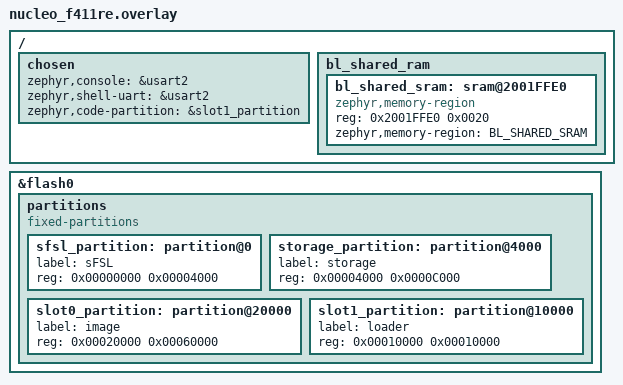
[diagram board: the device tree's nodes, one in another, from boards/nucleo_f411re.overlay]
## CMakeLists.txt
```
# SPDX-License-Identifier: Apache-2.0

cmake_minimum_required(VERSION 3.13.1)

# find_package(Zephyr) in order to load application boilerplate:
# http://docs.zephyrproject.org/application/application.html
find_package(Zephyr REQUIRED HINTS $ENV{ZEPHYR_BASE})

project(sFSL)

zephyr_include_directories(
    ${CMAKE_CURRENT_LIST_DIR}/include
)

zephyr_linker_sources(SECTIONS iterables.ld)

FILE(GLOB app_sources src/main.c src/uart_handle.c src/tshell.c)

target_sources(app PRIVATE ${app_sources})
```

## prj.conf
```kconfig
CONFIG_SBK=y
CONFIG_SBK_MINCRYPT=y
CONFIG_FLASH=y
CONFIG_MAIN_STACK_SIZE=1024
CONFIG_SYSTEM_WORKQUEUE_STACK_SIZE=4096
#CONFIG_PICOLIBC=y

CONFIG_USE_DT_CODE_PARTITION=y
CONFIG_ROM_START_OFFSET=0x200
CONFIG_BOOT_BANNER=n
CONFIG_CONSOLE=y
CONFIG_RING_BUFFER=y
CONFIG_UART_INTERRUPT_DRIVEN=y

CONFIG_LOG=y
CONFIG_SBK_LOG_LEVEL_DBG=y
CONFIG_LOG_MODE_MINIMAL=y
#CONFIG_CBPRINTF_NANO=y
```

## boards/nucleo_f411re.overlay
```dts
/*
 * Copyright (c) 2022 Laczen
 *
 * SPDX-License-Identifier: Apache-2.0
 */

/ {
	chosen {
		zephyr,console = &usart2;
		zephyr,shell-uart = &usart2;
		zephyr,code-partition = &slot1_partition;
	};
};

&flash0 {
	partitions {
		compatible = "fixed-partitions";
		#address-cells = <1>;
		#size-cells = <1>;

		sfsl_partition: partition@0 {
			label = "sFSL";
			reg = <0x00000000 0x00004000>;
		};

		storage_partition: partition@4000 {
			label = "storage";
			reg = <0x00004000 0x0000C000>;
		};

		slot0_partition: partition@20000 {
			label = "image";
			reg = <0x00020000 0x00060000>;
		};

		slot1_partition: partition@10000 {
			label = "loader";
			reg = <0x00010000 0x00010000>;
		};
	};
};

/ {
	bl_shared_ram {
		#address-cells = < 0x1 >;
		#size-cells = < 0x1 >;

		bl_shared_sram: sram@2001FFE0 {
			compatible = "zephyr,memory-region", "mmio-sram";
			reg = < 0x2001FFE0 0x0020 >;
			zephyr,memory-region = "BL_SHARED_SRAM";
		};
	};
};
```

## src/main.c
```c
/*
 * Copyright (c) 2022 Laczen
 *
 * SPDX-License-Identifier: Apache-2.0
 */

#include <stdarg.h>
#include <string.h>
#include <stdio.h>
#include <stdlib.h>
#include <zephyr/kernel.h>
#include <zephyr/drivers/flash.h>
#include <zephyr/device.h>
#include <zephyr/devicetree.h>
#include <zephyr/linker/devicetree_regions.h>

#include "sbk/sbk_image.h"
#include "sbk/sbk_os.h"
#include "sbk/sbk_util.h"
#include "sbk/sbk_product.h"

#include "tshell.h"
#include "uart_handle.h"

#define FLASH_OFFSET CONFIG_FLASH_BASE_ADDRESS

#define SLOT0_NODE		DT_NODELABEL(slot0_partition)
#define SLOT0_MTD               DT_MTD_FROM_FIXED_PARTITION(SLOT0_NODE)
#define SLOT0_DEVICE	        DEVICE_DT_GET(SLOT0_MTD)
#define SLOT0_OFFSET	        DT_REG_ADDR(SLOT0_NODE)
#define SLOT0_SIZE              DT_REG_SIZE(SLOT0_NODE)
#define SLOT1_NODE		DT_NODELABEL(slot1_partition)
#define SLOT1_MTD               DT_MTD_FROM_FIXED_PARTITION(SLOT1_NODE)
#define SLOT1_DEVICE	        DEVICE_DT_GET(SLOT1_MTD)
#define SLOT1_OFFSET	        DT_REG_ADDR(SLOT1_NODE)
#define SLOT1_SIZE              DT_REG_SIZE(SLOT1_NODE)

#define BL_SHARED_SRAM_NODE	DT_NODELABEL(bl_shared_sram)
#define BL_SHARED_SRAM_SECT	LINKER_DT_NODE_REGION_NAME(BL_SHARED_SRAM_NODE)
#define BL_SHARED_SRAM_ADDR	DT_REG_ADDR(BL_SHARED_SRAM_NODE)
#define BL_SHARED_SRAM_SIZE	DT_REG_SIZE(BL_SHARED_SRAM_NODE)

/**
 * @brief shared data format definition
 */

struct sbk_shared_data {
        uint32_t product_hash;
        struct sbk_version product_ver;
        uint8_t bslot;
        uint8_t bcnt;
};

/**
 * @brief Loader slot setup
 * 
 */

struct flash_slot_ctx {
        const struct device *dev;
        uint32_t off;
        uint32_t size;
};

const struct flash_slot_ctx slots[2] = {
        {
                .dev = SLOT0_DEVICE,
                .off = SLOT0_OFFSET,
                .size = SLOT0_SIZE,
        },
        {
                .dev = SLOT1_DEVICE,
                .off = SLOT1_OFFSET,
                .size = SLOT1_SIZE,
        }
};

static int read(const void *ctx, unsigned long off, void *data, size_t len)
{
        const struct flash_slot_ctx *sctx = (const struct flash_slot_ctx *)ctx;

        return flash_read(sctx->dev, sctx->off + off, data, len);
}

static int prog(const void *ctx, unsigned long off, const void *data, size_t len)
{
        const struct flash_slot_ctx *sctx = (const struct flash_slot_ctx *)ctx;
        int rc;

        if (((sctx->off + off) % 0x20000) == 0U) {
                rc = flash_erase(sctx->dev, sctx->off + off, 131072);
                if (rc != 0) {
                        goto end;
                }
        }

        rc = flash_write(sctx->dev, sctx->off + off, data, len);
        //SBK_LOG_DBG("Written %d bytes to %lx [%d]", len, sctx->off + off, rc);
end:
        return rc;
}

static int sync(const void *ctx)
{
        return 0;
}

static unsigned long get_start_address(const void *ctx)
{
        const struct flash_slot_ctx *sctx = (const struct flash_slot_ctx *)ctx;

        return FLASH_OFFSET + sctx->off;
}

static size_t get_size(const void *ctx)
{
        const struct flash_slot_ctx *sctx = (const struct flash_slot_ctx *)ctx;

        return sctx->size;
}

static int slot_init(struct sbk_os_slot *slot, unsigned int slot_no)
{
        if (slot_no >= ARRAY_SIZE(slots)) {
                return -SBK_EC_ENOENT;
        }

        slot->ctx = (void *)&slots[slot_no];
        slot->read = read;
        slot->prog = prog;
        slot->sync = sync;
        slot->get_start_address = get_start_address;
        slot->get_size = get_size;
        return 0;
}

int (*sbk_os_slot_init)(struct sbk_os_slot *slot, unsigned int slot_no) = slot_init;
struct sbk_shared_data shared_data Z_GENERIC_SECTION(BL_SHARED_SRAM);

/**
 * @brief Shell interface
 * 
 */

int cli_command_reboot(const struct tshell *tsh, int argc, char *argv[]) {
        tshell_put(tsh, "Rebooting");
        return 0;
}

#define IMG_BUF_SIZE 512
static size_t ldsize;
static size_t ldoffset;
static bool ldok;
static uint8_t img_buffer[IMG_BUF_SIZE];
static struct sbk_os_slot ldslot;
static struct sbk_image_buffer ldimage_buf = {
        .buf = img_buffer,
        .blen = IMG_BUF_SIZE,
};
static struct sbk_image ldimage = {
        .slot = &ldslot,
        .ib = &ldimage_buf,
};

void cli_load(const struct tshell *tsh, const char *data, size_t len)
{
        if (ldok) {
                if (sbk_image_write(&ldimage, ldoffset, data, len) != 0) {
                        tshell_put(tsh,"Write failed");
                        ldok = false;
                }
        }

        ldsize -= len;
        ldoffset += len;

        if (ldsize == 0U) {
                if (sbk_image_flush(&ldimage) == 0) {
                        tshell_put(tsh, "Write done");
                }

                tshell_set_bypass(tsh, NULL);
                return;
        }

        if ((ldoffset % 256) == 0) {
                tshell_put(tsh, "OK");
        }
}

int cli_command_load(const struct tshell *tsh, int argc, char *argv[]) {
        uint32_t slot;

        if (argc < 2) {
                tshell_put(tsh, "Insufficient arguments");
                return 0;
        }

        slot = strtoul(argv[1], NULL, 0);
        ldsize = strtoul(argv[2], NULL, 0);

        if (sbk_os_slot_open(&ldslot, slot) != 0) {
                tshell_put(tsh, "Bad slot specified");
                return 0;
        }

        if (sbk_os_slot_get_sz(&ldslot) < ldsize) {
                return 0;
        }

        ldoffset = 0U;
        ldok = true;

        char line[81];

        snprintf(line, sizeof(line), "Writing %d bytes to slot %d ...", ldsize, 
                 slot);
        tshell_put(tsh, line);
        tshell_set_bypass(tsh, cli_load);
        tshell_put(tsh, "OK");
        return 0;
}

int cli_command_ilist(const struct tshell *tsh, int argc, char *argv[]) {
        uint32_t slot_no = 0;
        struct sbk_os_slot slot;
        struct sbk_image image = {
                .slot = &slot,
        };
        struct sbk_version version;
	
        while (true) {
                char line[81];
                int rc;

                rc = sbk_os_slot_open(image.slot, slot_no);
                if (rc != 0) {
                        break;
                }
                rc = sbk_image_get_version(&image, &version);
                if (rc != 0) {
                        break;
                }
                snprintf(line, sizeof(line),
                         "Slot %d contains version %d.%d-%d", slot_no,
                         version.major, version.minor, version.revision);
                tshell_put(tsh, line);
                slot_no++;
        }

	return 0;

}

UART_HANDLE_DECLARE(uhndl, DEVICE_DT_GET(DT_CHOSEN(zephyr_console)), 512);
TSHELL_DECLARE(tsh, 64);

TSHELL_REGISTER_CMD(tsh, list, cli_command_ilist, "List images");
TSHELL_REGISTER_CMD(tsh, load, cli_command_load, "Load image to slot: [load slot_no bytes]");
TSHELL_REGISTER_CMD(tsh, reboot, cli_command_reboot, "Reboot device");

void main(void)
{
            
        SBK_LOG_INF("Welcome to %x version %d.%d-%d", shared_data.product_hash,
                shared_data.product_ver.major, 
                shared_data.product_ver.minor,
                shared_data.product_ver.revision);
        SBK_LOG_INF("Running from slot %d", shared_data.bslot);
        SBK_LOG_INF("Boot retries %d", shared_data.bcnt);

        uart_handle_register_rx_cb(&uhndl, tshell_receive, (void *)&tsh);
        tshell_register_send_cb(&tsh, uart_handle_tx, (void *)&uhndl);

        uart_handle_start(&uhndl);
        tshell_start(&tsh);

}
```

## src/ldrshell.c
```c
/*
 * Copyright (c) 2022 Laczen
 *
 * SPDX-License-Identifier: Apache-2.0
 */

#include <zephyr/shell/shell.h>
#include <zephyr/sys/util.h>
#include "sbk/sbk_os.h"
#include "sbk/sbk_product.h"
#include "sbk/sbk_image.h"

#include <stdlib.h>
#include <string.h>

/* Buffer is only needed for bytes that follow command and offset */
#define BUF_ARRAY_CNT (CONFIG_SHELL_ARGC_MAX - 2)

/* This only issues compilation error when it would not be possible
 * to extract at least one byte from command line arguments, yet
 * it does not warrant successful writes if BUF_ARRAY_CNT
 * is smaller than flash write alignment.
 */
BUILD_ASSERT(BUF_ARRAY_CNT >= 1);

#define IMG_BUF_SIZE 512
static struct k_mutex load_lock;
static uint32_t load_total;
static uint32_t load_written;
static uint8_t img_buffer[IMG_BUF_SIZE];
static struct sbk_os_slot load_slot;
static struct sbk_image_buffer load_image_buf = {
        .buf = img_buffer,
        .blen = IMG_BUF_SIZE,
};
static struct sbk_image load_image = {
        .slot = &load_slot,
        .ib = &load_image_buf,
};
static bool load_ok;

static int set_bypass(const struct shell *sh, shell_bypass_cb_t bypass)
{
	static bool in_use;

	if (bypass && in_use) {
		shell_error(sh, "load supports setting bypass on a single instance.");

		return -EBUSY;
	}

	/* Mark that we have set or unset the bypass function */
	in_use = bypass != NULL;

	if (in_use) {
		shell_print(sh, "Loading...");
	}

	shell_set_bypass(sh, bypass);

	return 0;
}


static void bypass_cb(const struct shell *sh, uint8_t *recv, size_t len)
{
	uint32_t left_to_read = load_total - load_written;
	uint32_t to_write = MIN(len, left_to_read);
        int rc;

        k_mutex_lock(&load_lock, K_FOREVER);

        if (load_ok) {
                rc = sbk_image_write(&load_image, load_written, recv, to_write);
                if (rc != 0) {
		        shell_error(sh, "Write failed at position %x [%d]",
			            load_written, rc);
                        load_ok = false;
	        }
        }

        load_written += to_write;

	if (load_written >= load_total) {
                shell_print(sh, "Write complete");
                if (load_ok) {
                        rc = sbk_image_flush(&load_image);
                }

		set_bypass(sh, NULL);
	}

        k_mutex_unlock(&load_lock);
}

static int cmd_load(const struct shell *sh, size_t argc, char *argv[])
{
	uint32_t image_no;

        image_no = strtoul(argv[1], NULL, 0);
	load_total = strtoul(argv[2], NULL, 0);

	/* Prepare image for callback. */
	if (sbk_os_slot_open(&load_slot, image_no) != 0) {
                shell_print(sh, "Error opening slot %d", image_no);
                goto end;                
        }

        load_ok = true;
        load_image.ib->bpos = 0U;
        load_image.ib->bstart = 0U;
        load_written = 0U;
        k_mutex_init(&load_lock);
	shell_print(sh, "Loading %d bytes to slot %d", load_total, image_no);
	set_bypass(sh, bypass_cb);

end:
	return 0;
}

static int cmd_list(const struct shell *sh, size_t argc, char *argv[])
{
	uint32_t slot_no = 0;
        struct sbk_version version;
	
        while (true) {
                int rc;

                rc = sbk_os_slot_open(load_image.slot, slot_no);
                if (rc != 0) {
                        break;
                }
                rc = sbk_image_get_version(&load_image, &version);
                if (rc != 0) {
                        break;
                }
                shell_print(sh, "Slot %d contains version %d.%d-%d", slot_no,
                            version.major, version.minor, version.revision);
                slot_no++;
        }

	return 0;
}

SHELL_STATIC_SUBCMD_SET_CREATE(ldrshell_cmds,
	SHELL_CMD_ARG(load, NULL,
		"<image> <size>",
		cmd_load, 2, 1),
        SHELL_CMD_ARG(list, NULL,
		"list images",
		cmd_list, 0, 1),
	SHELL_SUBCMD_SET_END
);

static int cmd_ldrshell(const struct shell *shell, size_t argc, char **argv)
{
	shell_error(shell, "%s:unknown parameter: %s", argv[0], argv[1]);
	return -EINVAL;
}

SHELL_CMD_ARG_REGISTER(ldrshell, &ldrshell_cmds, "Image loader shell commands",
		       cmd_ldrshell, 2, 0);
```

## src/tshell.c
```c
#include <stdbool.h>
#include <stddef.h>
#include <string.h>
#include <zephyr/kernel.h>
#include "tshell.h"

#define TSHELL_MAX_ARGS (16)
#define TSHELL_PROMPT "tshell> "

void tshell_register_send_cb(struct tshell *tsh,
			     void (*send_cb)(const void *send_cb_ctx, char c),
			     void *send_cb_ctx)
{
	tsh->send_cb = send_cb;
	tsh->send_cb_ctx = send_cb_ctx;
}

static void tshell_send(const struct tshell *tsh, char c)
{
        if (tsh->send_cb == NULL) {
                return;
        }
        return tsh->send_cb(tsh->send_cb_ctx, c);
}

static void tshell_echo(const struct tshell *tsh, char c)
{
        if (c == '\n' || c == '\r') {
                tshell_send(tsh, '\r');
                tshell_send(tsh, '\n');
        }  else {
                tshell_send(tsh, c);
        }
}

static void tshell_echo_str(const struct tshell *tsh, const char *str)
{
        for (const char *c = str; *c != '\0'; ++c) {
                tshell_echo(tsh, *c);
        }
}

static void tshell_send_prompt(const struct tshell *tsh)
{
        tshell_echo_str(tsh, TSHELL_PROMPT);
}

static struct tshell_command *tshell_find_cmd(const struct tshell *tsh,
                                              const char *cmd)
{
        STRUCT_SECTION_FOREACH(tshell_command, h) {
                if ((strcmp(h->sname, tsh->name)==0) && 
                    (strcmp(h->cmd, cmd)== 0)) {
                        return h;
                }
        
        }

        return NULL;
}

static bool tshell_cmdbuf_full(const struct tshell *tsh)
{
  return tsh->tsh_data->cmdbufpos >= tsh->tsh_data->cmdbufsize;
}

static void tshell_cmdbuf_reset(const struct tshell *tsh)
{
        memset(tsh->tsh_data->cmdbuf, 0, tsh->tsh_data->cmdbufsize);
        tsh->tsh_data->cmdbufpos = 0U;
}

static void tshell_process(const struct tshell *tsh)
{
        char *argv[TSHELL_MAX_ARGS] = {0};
        int argc = 0;
        char *next_arg = NULL;

        for (size_t i = 0; i < tsh->tsh_data->cmdbufpos; ++i) {
                char *const c = &tsh->tsh_data->cmdbuf[i];

                if ((*c == ' ') || (i == (tsh->tsh_data->cmdbufpos - 1))) {
                        *c = '\0';
                        if (next_arg) {
                                argv[argc++] = next_arg;
                                next_arg = NULL;
                        }
                } else if (!next_arg) {
                        next_arg = c;
                }

                if (argc == TSHELL_MAX_ARGS) {
                        break;
                }
        }

        if (tsh->tsh_data->cmdbufpos == tsh->tsh_data->cmdbufsize) {
                tshell_echo(tsh, '\n');
        }

        if (argc >= 1) {
                const struct tshell_command *command = tshell_find_cmd(tsh, argv[0]);
                if (!command) {
                        tshell_echo_str(tsh, "Unknown command: ");
                        tshell_echo_str(tsh, argv[0]);
                        tshell_echo(tsh, '\n');
                        tshell_echo_str(tsh, "Type 'help' to list commands\n");
                } else {
                        command->handler(tsh, argc, argv);
                }
        }

        tshell_cmdbuf_reset(tsh);
        if (tsh->tsh_data->bypass == NULL) {
                tshell_send_prompt(tsh);
        }
}


void tshell_receive(const void *ctx, const char *data, size_t len)
{
        const struct tshell *tsh = (const struct tshell *)ctx;
        
        if (tsh->tsh_data->bypass != NULL) {
                tsh->tsh_data->bypass(tsh, data, len);
                return;
        }

        char *cdata = (char *)data;
        
        while (len != 0U) {
                char c = (*cdata);

                cdata++;
                len--;

                /* ignore empty lines */
                if (((c == '\n') || (c == '\r') || (c == '\b')) &&
                     (tsh->tsh_data->cmdbufpos == 0U))  {
                        continue;
                }

                tshell_echo(tsh, c);
                
                if (c == '\b') {
                        tsh->tsh_data->cmdbufpos--;
                        tshell_echo(tsh, ' ');
                        tshell_echo(tsh, '\b');
                } else {
                        tsh->tsh_data->cmdbuf[tsh->tsh_data->cmdbufpos++] = c;
                }
                
                if ((c == '\r') || (c == '\n') || tshell_cmdbuf_full(tsh)) {
                        tshell_process(tsh);
                }
        }

}

void tshell_start(const struct tshell *tsh)
{
        tshell_cmdbuf_reset(tsh);
        tshell_echo_str(tsh, "\n" TSHELL_PROMPT);
}

void tshell_set_bypass(const struct tshell *tsh, 
                       void (*bypass)(const struct tshell *tsh, const char *c,
                                      size_t len))
{
        tsh->tsh_data->bypass = bypass;
        if (tsh->tsh_data->bypass == NULL) {
                tshell_echo_str(tsh, "\n" TSHELL_PROMPT);
        }
}

void tshell_put(const struct tshell *tsh, const char *str) {
        tshell_echo_str(tsh, str);
        tshell_echo(tsh, '\n');
}

int tshell_help_handler(const struct tshell *tsh, int argc, char *argv[]) {
        STRUCT_SECTION_FOREACH(tshell_command, h) {
                if (strcmp(h->sname, tsh->name) == 0) {
                        tshell_echo_str(tsh, h->cmd);
                        tshell_echo_str(tsh, ": ");
                        tshell_echo_str(tsh, h->help);
                        tshell_echo(tsh, '\n');
                }
        
        }

        return 0;
}
```

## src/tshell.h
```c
/*
 * TinyShell (tshell)
 *
 * Copyright (c) 2022 Laczen
 *
 * SPDX-License-Identifier: Apache-2.0
 */

#ifndef TSHELL_H_
#define TSHELL_H_

#ifdef __cplusplus
extern "C" {
#endif

#include <stddef.h>

struct tshell;

struct tshell_command {
	const char *sname;	/* name of the shell it belongs to */
        const char *cmd;  	/* command string */
        int (*handler)(const struct tshell *tsh, int argc, char *argv[]);
        const char *help;	/* help string */
};

/**
 * @brief TSHELL_REGISTER_CMD: register a tshell command
 * 
 * @param _sname: shell the command belongs to
 * @param _cmd: the command to register (one word)
 * @param _handler: handler function
 * @param _help: help string
 * 
 * e.g. TSHELL_REGISTER_CMD(tsh, list, list_command, "List Images"), registers
 * a command "list" with tshell tsh, when issued in the shell executes 
 * list_command and returns "List Images" as help string.  
 * 
 */
#define TSHELL_REGISTER_CMD(_sname, _cmd, _handler, _help) 		       \
	const STRUCT_SECTION_ITERABLE(tshell_command, 			       \
				      tshell ## _ ## _sname ## _ ## _cmd) = {  \
		.sname = STRINGIFY(_sname),				       \
		.cmd = STRINGIFY(_cmd),					       \
                .handler = _handler,					       \
                .help = _help, 				       		       \
        }

int tshell_help_handler(const struct tshell *tsh, int argc, char *argv[]);

struct tshell_data {
	char *cmdbuf;
	size_t cmdbufpos;
	const size_t cmdbufsize;
	void (*bypass)(const struct tshell *tsh, const char *data, size_t len);
};

struct tshell {
	char *name;
	struct tshell_data *tsh_data;
	void (*send_cb)(const void *send_cb_ctx, char c);
	void *send_cb_ctx;
};

/**
 * @brief TSHELL_DECLARE creates a tshell variable and registers a help
 *        command for it
 * 
 * @param _name: shell name
 * @param _bufsize: size of the buffer to store commands while they are typed
 * 
 */
#define TSHELL_DECLARE(_name, _bufsize)					       \
	static char _name ## _tshell_cmdbuf[_bufsize];		       	       \
	static struct tshell_data _name ## _tshell_data = {		       \
		.cmdbuf = _name ## _tshell_cmdbuf,			       \
		.cmdbufsize = _bufsize,					       \
	};								       \
	static struct tshell _name = {				       	       \
		.name = STRINGIFY(_name) ,				       \
		.tsh_data = & _name ## _tshell_data,			       \
	};								       \
	TSHELL_REGISTER_CMD(_name, help, tshell_help_handler, "List all commands")


/**
 * @brief tshell_register_send_cb
 * 
 * Register a routine that needs to be called for sending data to the shell user
 * and also provide a (opaque) context for this routine.
 * 
 * @param tsh: shell instance
 * @param send_cb: callback routine 
 * @param send_cb_ctx: callback routine (opaque) context 
 */
void tshell_register_send_cb(struct tshell *tsh,
			     void (*send_cb)(const void *send_cb_ctx, char c),
			     void *send_cb_ctx);

/**
 * @brief tshell_receive
 * 
 * routine that should be called whenever data for the shell needs to be
 * processed
 * 
 * @param ctx: opaque context (this is casted to a (struct shell *))
 * @param data: data that needs processing
 * @param len:  data length
 */
void tshell_receive(const void *ctx, const char *data, size_t len);

/**
 * @brief tshell_start
 * 
 * @param tsh: shell instance to start
 */
void tshell_start(const struct tshell *tsh);

/**
 * @brief tshell_set_bypass
 * 
 * The shell processing can be bypassed to a provided routine, when done
 * bypassing the bypass routine needs to be reset to NULL
 * 
 * @param tsh: shell instance
 * @param bypass: bypass routine 
 */
void tshell_set_bypass(const struct tshell *tsh,
		       void (*bypass)(const struct tshell *tsh,
		       		      const char *data, size_t len));

/**
 * @brief tshell_put
 * 
 * Routine to return info to the shell user
 * 
 * @param tsh: shell instance
 * @param str: info to return
 */
void tshell_put(const struct tshell *tsh, const char *str);

#ifdef __cplusplus
}
#endif

#endif /* TSHELL_H_*/
```

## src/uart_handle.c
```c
#include <zephyr/drivers/uart.h>

#include "uart_handle.h"

static void uart_irq_callback(const struct device *dev, void *user_data)
{
        struct uart_handle *uhndl = (struct uart_handle *)user_data;

	uart_irq_update(dev);

	if (!uart_irq_rx_ready(dev)) {
		return;
	}

        uint8_t *data;
        size_t len, rd_len;
        bool new_data = false;

        do {
                len = ring_buf_put_claim(uhndl->rb, &data, uhndl->rb->size);
		if (len > 0) {
			rd_len = uart_fifo_read(dev, data, len);
                        new_data = true;
			int err = ring_buf_put_finish(uhndl->rb, rd_len);
			(void)err;
		} else {
			uint8_t dummy;

			/* No space in the ring buffer - consume byte. */
			//LOG_WRN("RX ring buffer full.");
			rd_len = uart_fifo_read(dev, &dummy, 1);
		}
	} while (rd_len && (rd_len == len));

        if (new_data) {
                /* add task to workqueue */
                k_work_submit(&uhndl->rx_work);

        }
}

void uart_handle_register_rx_cb(struct uart_handle *uhndl,
                                void (*rx_cb)(const void *rx_cb_ctx,
                                              const char *data, size_t len),
                                void *rx_cb_ctx)
{
        uhndl->rx_cb = rx_cb;
        uhndl->rx_cb_ctx = rx_cb_ctx;
}

void uart_handle_tx(const void *ctx, char c)
{
        const struct uart_handle *uhndl = (const struct uart_handle *)ctx;

        uart_poll_out(uhndl->dev, c);
}

void uart_handle_process_rx_queue(struct k_work *work)
{
        struct uart_handle *uhndl = CONTAINER_OF(work, struct uart_handle, rx_work);
        const uint8_t *data;
        size_t len;
                        
        len = ring_buf_get_claim(uhndl->rb, (uint8_t **)&data, uhndl->rb->size);
        if (uhndl->rx_cb != NULL) {
                uhndl->rx_cb(uhndl->rx_cb_ctx, data, len);
        }
        ring_buf_get_finish(uhndl->rb, len);
}

void uart_handle_start(struct uart_handle *uhndl)
{

        k_work_init(&uhndl->rx_work, uart_handle_process_rx_queue);

        ring_buf_reset(uhndl->rb);
        uart_irq_callback_user_data_set(uhndl->dev, uart_irq_callback,
                                        (void *)uhndl);
        /* Drain the fifo */
	if (uart_irq_rx_ready(uhndl->dev)) {
		uint8_t c;

		while (uart_fifo_read(uhndl->dev, &c, 1));
	}

	uart_irq_rx_enable(uhndl->dev);
}
```

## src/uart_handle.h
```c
/*
 * uart implementation
 *
 * Copyright (c) 2022 Laczen
 *
 * SPDX-License-Identifier: Apache-2.0
 */

#include <stdlib.h>
#include <zephyr/kernel.h>
#include <zephyr/sys/ring_buffer.h>
#include <zephyr/device.h>

/**
 * @brief Uart handling
 * 
 */
struct uart_handle {
        const struct device *dev;
        struct ring_buf *rb;
        struct k_work rx_work;
        void (*rx_cb)(const void *rx_cb_ctx, const char *data, size_t len);         
        void *rx_cb_ctx;
};

#define UART_HANDLE_DECLARE(_name, _dev, _rbsize)                              \
        RING_BUF_DECLARE(_name##_rx_rb, _rbsize);                              \
        static struct uart_handle _name = {                                    \
                .dev = _dev,                                                   \
                .rb = &_name##_rx_rb,                                          \
        };

void uart_handle_register_rx_cb(struct uart_handle *uhndl,
                                void (*rx_cb)(const void *rx_cb_ctx,
                                              const char *data, size_t len),
                                void *rx_cb_ctx);

void uart_handle_tx(const void *ctx, char c);

void uart_handle_start(struct uart_handle *uhndl);
```
